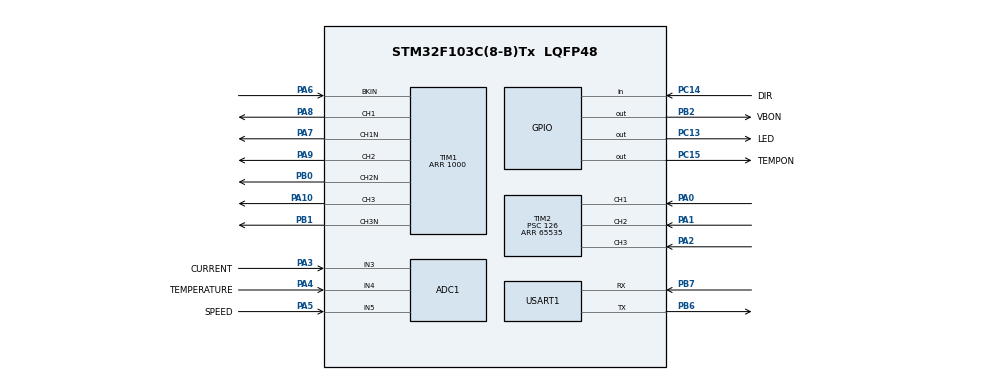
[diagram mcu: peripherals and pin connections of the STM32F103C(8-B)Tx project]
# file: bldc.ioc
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ADC1.Channel-2\#ChannelRegularConversion=ADC_CHANNEL_3
ADC1.NbrOfConversionFlag=1
ADC1.Rank-2\#ChannelRegularConversion=1
ADC1.SamplingTime-2\#ChannelRegularConversion=ADC_SAMPLETIME_1CYCLE_5
ADC1.master=1
Mcu.Family=STM32F1
Mcu.Name=STM32F103C(8-B)Tx
Mcu.Package=LQFP48
NVIC.PriorityGroup=NVIC_PRIORITYGROUP_4
NVIC.TIM1_BRK_IRQn=true\:0\:0\:false\:false\:true\:true\:true
NVIC.TIM1_CC_IRQn=true\:0\:0\:false\:false\:true\:true\:true
NVIC.TIM1_TRG_COM_IRQn=true\:0\:0\:false\:false\:true\:true\:true
NVIC.TIM1_UP_IRQn=true\:0\:0\:false\:false\:true\:true\:true
NVIC.TIM2_IRQn=true\:0\:0\:false\:false\:true\:true\:true
NVIC.USART1_IRQn=true\:0\:0\:false\:false\:true\:true\:true
PA0-WKUP.GPIO_PuPd=GPIO_PULLUP
PA0-WKUP.Signal=S_TIM2_CH1_ETR
PA1.GPIO_PuPd=GPIO_PULLUP
PA1.Signal=S_TIM2_CH2
PA10.GPIO_Speed=GPIO_SPEED_FREQ_HIGH
PA10.Signal=S_TIM1_CH3
PA13.Mode=Serial_Wire
PA13.Signal=SYS_JTMS-SWDIO
PA14.Mode=Serial_Wire
PA14.Signal=SYS_JTCK-SWCLK
PA2.GPIO_PuPd=GPIO_PULLUP
PA2.Signal=S_TIM2_CH3
PA3.GPIO_Label=CURRENT
PA3.Signal=ADCx_IN3
PA4.GPIO_Label=TEMPERATURE
PA4.Signal=ADCx_IN4
PA5.GPIO_Label=SPEED
PA5.Signal=ADCx_IN5
PA6.GPIO_PuPd=GPIO_PULLUP
PA6.Mode=Activate-Break-Input
PA6.Signal=TIM1_BKIN
PA7.GPIO_Speed=GPIO_SPEED_FREQ_HIGH
PA7.Mode=PWM Generation1 CH1 CH1N
PA7.Signal=TIM1_CH1N
PA8.GPIO_Speed=GPIO_SPEED_FREQ_HIGH
PA8.Signal=S_TIM1_CH1
PA9.GPIO_Speed=GPIO_SPEED_FREQ_HIGH
PA9.Signal=S_TIM1_CH2
PB0.GPIO_Speed=GPIO_SPEED_FREQ_HIGH
PB0.Mode=PWM Generation2 CH2 CH2N
PB0.Signal=TIM1_CH2N
PB1.GPIO_Speed=GPIO_SPEED_FREQ_HIGH
PB1.Mode=PWM Generation3 CH3 CH3N
PB1.Signal=TIM1_CH3N
PB2.GPIO_Label=VBON
PB2.Signal=GPIO_Output
PB6.Mode=Asynchronous
PB6.Signal=USART1_TX
PB7.Mode=Asynchronous
PB7.Signal=USART1_RX
PC13-TAMPER-RTC.GPIO_Label=LED
PC13-TAMPER-RTC.Signal=GPIO_Output
PC14-OSC32_IN.GPIO_Label=DIR
PC14-OSC32_IN.Signal=GPIO_Input
PC15-OSC32_OUT.GPIO_Label=TEMPON
PC15-OSC32_OUT.Signal=GPIO_Output
PD0-OSC_IN.Mode=HSE-External-Oscillator
PD0-OSC_IN.Signal=RCC_OSC_IN
PD1-OSC_OUT.Mode=HSE-External-Oscillator
PD1-OSC_OUT.Signal=RCC_OSC_OUT
ProjectManager.HeapSize=0x200
ProjectManager.StackSize=0x400
ProjectManager.TargetToolchain=Other Toolchains (GPDSC)
RCC.ADCPresc=RCC_ADCPCLK2_DIV8
RCC.AHBFreq_Value=72000000
RCC.APB1CLKDivider=RCC_HCLK_DIV2
RCC.APB1Freq_Value=36000000
RCC.APB1TimFreq_Value=72000000
RCC.APB2Freq_Value=72000000
RCC.APB2TimFreq_Value=72000000
RCC.HCLKFreq_Value=72000000
RCC.PLLMUL=RCC_PLL_MUL9
RCC.PLLSourceVirtual=RCC_PLLSOURCE_HSE
RCC.RTCClockSelection=RCC_RTCCLKSOURCE_LSE
RCC.SYSCLKFreq_VALUE=72000000
RCC.SYSCLKSource=RCC_SYSCLKSOURCE_PLLCLK
RCC.USBFreq_Value=72000000
SH.ADCx_IN3.0=ADC1_IN3,IN3
SH.ADCx_IN4.0=ADC1_IN4,IN4
SH.ADCx_IN5.0=ADC1_IN5,IN5
SH.S_TIM1_CH1.0=TIM1_CH1,PWM Generation1 CH1 CH1N
SH.S_TIM1_CH2.0=TIM1_CH2,PWM Generation2 CH2 CH2N
SH.S_TIM1_CH3.0=TIM1_CH3,PWM Generation3 CH3 CH3N
SH.S_TIM2_CH1_ETR.0=TIM2_CH1,Xored_Inputs_Hall_Sensor_Interface
SH.S_TIM2_CH2.0=TIM2_CH2,Xored_Inputs_Hall_Sensor_Interface
SH.S_TIM2_CH3.0=TIM2_CH3,Xored_Inputs_Hall_Sensor_Interface
TIM1.BreakPolarity=TIM_BREAKPOLARITY_LOW
TIM1.Channel-PWM\ Generation1\ CH1\ CH1N=TIM_CHANNEL_1
TIM1.Channel-PWM\ Generation2\ CH2\ CH2N=TIM_CHANNEL_2
TIM1.Channel-PWM\ Generation3\ CH3\ CH3N=TIM_CHANNEL_3
TIM1.OCIdleState_1=TIM_OCIDLESTATE_SET
TIM1.OCIdleState_2=TIM_OCIDLESTATE_SET
TIM1.OCIdleState_3=TIM_OCIDLESTATE_SET
TIM1.OCNIdleState_1=TIM_OCNIDLESTATE_SET
TIM1.OCNIdleState_2=TIM_OCNIDLESTATE_SET
TIM1.OCNIdleState_3=TIM_OCNIDLESTATE_SET
TIM1.Period=1000
TIM1.TIM_MasterSlaveMode=TIM_MASTERSLAVEMODE_ENABLE
TIM2.AutoReloadPreload=TIM_AUTORELOAD_PRELOAD_DISABLE
TIM2.Channel-Output\ Compare4\ No\ Output=TIM_CHANNEL_4
TIM2.Commutation_Delay=100
TIM2.IC1Filter=0x0F
TIM2.Period=65535
TIM2.Prescaler=126
TIM2.Pulse-Output\ Compare4\ No\ Output=1
USART1.VirtualMode=VM_ASYNC
VP_ADC1_TempSens_Input.Mode=IN-TempSens
VP_ADC1_Vref_Input.Mode=IN-Vrefint
VP_TIM1_VS_ClockSourceINT.Mode=Internal
VP_TIM1_VS_ClockSourceITR.Mode=TriggerSource_ITR1
VP_TIM1_VS_ControllerModeReset.Mode=Reset Mode
VP_TIM2_VS_ClockSourceINT.Mode=Internal
VP_TIM2_VS_no_output4.Mode=Output Compare4 No Output
board=custom

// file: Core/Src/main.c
/* USER CODE BEGIN Header */
/**
  ******************************************************************************
  * @file           : main.c
  * @brief          : Main program body
  ******************************************************************************
  * @attention
  *
  * <h2><center>&copy; Copyright (c) 2019 STMicroelectronics.
  * All rights reserved.</center></h2>
  *
  * This software component is licensed by ST under BSD 3-Clause license,
  * the "License"; You may not use this file except in compliance with the
  * License. You may obtain a copy of the License at:
  *                        opensource.org/licenses/BSD-3-Clause
  *
  ******************************************************************************
  */
/* USER CODE END Header */

#include "main.h"

/* USER CODE BEGIN Includes */
#include "bldc.h"
/* USER CODE END Includes */

void SystemClock_Config(void);
static void MX_GPIO_Init(void);
static void MX_TIM1_Init(void);
static void MX_TIM2_Init(void);
static void MX_USART1_UART_Init(void);
static void MX_ADC1_Init(void);

int main(void)
{

  /* MCU Configuration--------------------------------------------------------*/

  /* Reset of all peripherals, Initializes the Flash interface and the Systick. */

  LL_APB2_GRP1_EnableClock(LL_APB2_GRP1_PERIPH_AFIO);
  LL_APB1_GRP1_EnableClock(LL_APB1_GRP1_PERIPH_PWR);

  NVIC_SetPriorityGrouping(NVIC_PRIORITYGROUP_4);

  /* System interrupt init*/

  /** NOJTAG: JTAG-DP Disabled and SW-DP Enabled
  */
  LL_GPIO_AF_Remap_SWJ_NOJTAG();

  /* Configure the system clock */
  SystemClock_Config();

  /* Initialize all configured peripherals */
  MX_GPIO_Init();
  MX_TIM1_Init();
  MX_TIM2_Init();
  MX_USART1_UART_Init();
  MX_ADC1_Init();
  /* USER CODE BEGIN 2 */

  BLDC_SystemInit();

  /* USER CODE END 2 */

  /* Infinite loop */
  while (1)
  {

  }
}

void SystemClock_Config(void)
{
  LL_FLASH_SetLatency(LL_FLASH_LATENCY_2);

   if(LL_FLASH_GetLatency() != LL_FLASH_LATENCY_2)
  {
    Error_Handler();
  }
  LL_RCC_HSE_Enable();

   /* Wait till HSE is ready */
  while(LL_RCC_HSE_IsReady() != 1)
  {

  }
  LL_RCC_PLL_ConfigDomain_SYS(LL_RCC_PLLSOURCE_HSE_DIV_1, LL_RCC_PLL_MUL_9);
  LL_RCC_PLL_Enable();

   /* Wait till PLL is ready */
  while(LL_RCC_PLL_IsReady() != 1)
  {

  }
  LL_RCC_SetAHBPrescaler(LL_RCC_SYSCLK_DIV_1);
  LL_RCC_SetAPB1Prescaler(LL_RCC_APB1_DIV_2);
  LL_RCC_SetAPB2Prescaler(LL_RCC_APB2_DIV_1);
  LL_RCC_SetSysClkSource(LL_RCC_SYS_CLKSOURCE_PLL);

   /* Wait till System clock is ready */
  while(LL_RCC_GetSysClkSource() != LL_RCC_SYS_CLKSOURCE_STATUS_PLL)
  {

  }
  LL_Init1msTick(72000000);
  LL_SYSTICK_SetClkSource(LL_SYSTICK_CLKSOURCE_HCLK);
  LL_SetSystemCoreClock(72000000);
  LL_RCC_SetADCClockSource(LL_RCC_ADC_CLKSRC_PCLK2_DIV_8);
}

static void MX_ADC1_Init(void)
{

  LL_ADC_InitTypeDef ADC_InitStruct = {0};
  LL_ADC_CommonInitTypeDef ADC_CommonInitStruct = {0};
  LL_ADC_REG_InitTypeDef ADC_REG_InitStruct = {0};

  LL_GPIO_InitTypeDef GPIO_InitStruct = {0};

  /* Peripheral clock enable */
  LL_APB2_GRP1_EnableClock(LL_APB2_GRP1_PERIPH_ADC1);

  LL_APB2_GRP1_EnableClock(LL_APB2_GRP1_PERIPH_GPIOA);
  /**ADC1 GPIO Configuration
  PA3   ------> ADC1_IN3
  PA4   ------> ADC1_IN4
  PA5   ------> ADC1_IN5
  */
  GPIO_InitStruct.Pin = CURRENT_Pin|TEMPERATURE_Pin|SPEED_Pin;
  GPIO_InitStruct.Mode = LL_GPIO_MODE_ANALOG;
  LL_GPIO_Init(GPIOA, &GPIO_InitStruct);

  /** Common config
  */
  ADC_InitStruct.DataAlignment = LL_ADC_DATA_ALIGN_RIGHT;
  ADC_InitStruct.SequencersScanMode = LL_ADC_SEQ_SCAN_DISABLE;
  LL_ADC_Init(ADC1, &ADC_InitStruct);
  ADC_CommonInitStruct.Multimode = LL_ADC_MULTI_INDEPENDENT;
  LL_ADC_CommonInit(__LL_ADC_COMMON_INSTANCE(ADC1), &ADC_CommonInitStruct);
  ADC_REG_InitStruct.TriggerSource = LL_ADC_REG_TRIG_SOFTWARE;
  ADC_REG_InitStruct.SequencerLength = LL_ADC_REG_SEQ_SCAN_DISABLE;
  ADC_REG_InitStruct.SequencerDiscont = LL_ADC_REG_SEQ_DISCONT_DISABLE;
  ADC_REG_InitStruct.ContinuousMode = LL_ADC_REG_CONV_SINGLE;
  ADC_REG_InitStruct.DMATransfer = LL_ADC_REG_DMA_TRANSFER_NONE;
  LL_ADC_REG_Init(ADC1, &ADC_REG_InitStruct);
  /** Configure Regular Channel
  */
  LL_ADC_REG_SetSequencerRanks(ADC1, LL_ADC_REG_RANK_1, LL_ADC_CHANNEL_3);
  LL_ADC_SetChannelSamplingTime(ADC1, LL_ADC_CHANNEL_3, LL_ADC_SAMPLINGTIME_1CYCLE_5);

}

static void MX_TIM1_Init(void)
{

  LL_TIM_InitTypeDef TIM_InitStruct = {0};
  LL_TIM_OC_InitTypeDef TIM_OC_InitStruct = {0};
  LL_TIM_BDTR_InitTypeDef TIM_BDTRInitStruct = {0};

  LL_GPIO_InitTypeDef GPIO_InitStruct = {0};

  /* Peripheral clock enable */
  LL_APB2_GRP1_EnableClock(LL_APB2_GRP1_PERIPH_TIM1);

  LL_APB2_GRP1_EnableClock(LL_APB2_GRP1_PERIPH_GPIOA);
  /**TIM1 GPIO Configuration
  PA6   ------> TIM1_BKIN
  */
  GPIO_InitStruct.Pin = LL_GPIO_PIN_6;
  GPIO_InitStruct.Mode = LL_GPIO_MODE_INPUT;
  GPIO_InitStruct.Pull = LL_GPIO_PULL_UP;
  LL_GPIO_Init(GPIOA, &GPIO_InitStruct);

  /* TIM1 interrupt Init */
  NVIC_SetPriority(TIM1_BRK_IRQn, NVIC_EncodePriority(NVIC_GetPriorityGrouping(),0, 0));
  NVIC_EnableIRQ(TIM1_BRK_IRQn);
  NVIC_SetPriority(TIM1_UP_IRQn, NVIC_EncodePriority(NVIC_GetPriorityGrouping(),0, 0));
  NVIC_EnableIRQ(TIM1_UP_IRQn);
  NVIC_SetPriority(TIM1_TRG_COM_IRQn, NVIC_EncodePriority(NVIC_GetPriorityGrouping(),0, 0));
  NVIC_EnableIRQ(TIM1_TRG_COM_IRQn);
  NVIC_SetPriority(TIM1_CC_IRQn, NVIC_EncodePriority(NVIC_GetPriorityGrouping(),0, 0));
  NVIC_EnableIRQ(TIM1_CC_IRQn);

  TIM_InitStruct.Prescaler = 0;
  TIM_InitStruct.CounterMode = LL_TIM_COUNTERMODE_UP;
  TIM_InitStruct.Autoreload = 1000;
  TIM_InitStruct.ClockDivision = LL_TIM_CLOCKDIVISION_DIV1;
  TIM_InitStruct.RepetitionCounter = 0;
  LL_TIM_Init(TIM1, &TIM_InitStruct);
  LL_TIM_DisableARRPreload(TIM1);
  LL_TIM_SetClockSource(TIM1, LL_TIM_CLOCKSOURCE_INTERNAL);
  LL_TIM_OC_EnablePreload(TIM1, LL_TIM_CHANNEL_CH1);
  TIM_OC_InitStruct.OCMode = LL_TIM_OCMODE_PWM1;
  TIM_OC_InitStruct.OCState = LL_TIM_OCSTATE_DISABLE;
  TIM_OC_InitStruct.OCNState = LL_TIM_OCSTATE_DISABLE;
  TIM_OC_InitStruct.CompareValue = 0;
  TIM_OC_InitStruct.OCPolarity = LL_TIM_OCPOLARITY_HIGH;
  TIM_OC_InitStruct.OCNPolarity = LL_TIM_OCPOLARITY_HIGH;
  TIM_OC_InitStruct.OCIdleState = LL_TIM_OCIDLESTATE_HIGH;
  TIM_OC_InitStruct.OCNIdleState = LL_TIM_OCIDLESTATE_HIGH;
  LL_TIM_OC_Init(TIM1, LL_TIM_CHANNEL_CH1, &TIM_OC_InitStruct);
  LL_TIM_OC_DisableFast(TIM1, LL_TIM_CHANNEL_CH1);
  LL_TIM_OC_EnablePreload(TIM1, LL_TIM_CHANNEL_CH2);
  TIM_OC_InitStruct.OCState = LL_TIM_OCSTATE_DISABLE;
  TIM_OC_InitStruct.OCNState = LL_TIM_OCSTATE_DISABLE;
  LL_TIM_OC_Init(TIM1, LL_TIM_CHANNEL_CH2, &TIM_OC_InitStruct);
  LL_TIM_OC_DisableFast(TIM1, LL_TIM_CHANNEL_CH2);
  LL_TIM_OC_EnablePreload(TIM1, LL_TIM_CHANNEL_CH3);
  TIM_OC_InitStruct.OCState = LL_TIM_OCSTATE_DISABLE;
  TIM_OC_InitStruct.OCNState = LL_TIM_OCSTATE_DISABLE;
  LL_TIM_OC_Init(TIM1, LL_TIM_CHANNEL_CH3, &TIM_OC_InitStruct);
  LL_TIM_OC_DisableFast(TIM1, LL_TIM_CHANNEL_CH3);
  LL_TIM_SetTriggerInput(TIM1, LL_TIM_TS_ITR1);
  LL_TIM_SetSlaveMode(TIM1, LL_TIM_SLAVEMODE_RESET);
  LL_TIM_DisableIT_TRIG(TIM1);
  LL_TIM_DisableDMAReq_TRIG(TIM1);
  LL_TIM_SetTriggerOutput(TIM1, LL_TIM_TRGO_RESET);
  LL_TIM_EnableMasterSlaveMode(TIM1);
  TIM_BDTRInitStruct.OSSRState = LL_TIM_OSSR_DISABLE;
  TIM_BDTRInitStruct.OSSIState = LL_TIM_OSSI_DISABLE;
  TIM_BDTRInitStruct.LockLevel = LL_TIM_LOCKLEVEL_OFF;
  TIM_BDTRInitStruct.DeadTime = 0;
  TIM_BDTRInitStruct.BreakState = LL_TIM_BREAK_ENABLE;
  TIM_BDTRInitStruct.BreakPolarity = LL_TIM_BREAK_POLARITY_LOW;
  TIM_BDTRInitStruct.AutomaticOutput = LL_TIM_AUTOMATICOUTPUT_DISABLE;
  LL_TIM_BDTR_Init(TIM1, &TIM_BDTRInitStruct);
  LL_APB2_GRP1_EnableClock(LL_APB2_GRP1_PERIPH_GPIOA);
  LL_APB2_GRP1_EnableClock(LL_APB2_GRP1_PERIPH_GPIOB);
  /**TIM1 GPIO Configuration
  PA7   ------> TIM1_CH1N
  PB0   ------> TIM1_CH2N
  PB1   ------> TIM1_CH3N
  PA8   ------> TIM1_CH1
  PA9   ------> TIM1_CH2
  PA10   ------> TIM1_CH3
  */
  GPIO_InitStruct.Pin = LL_GPIO_PIN_7|LL_GPIO_PIN_8|LL_GPIO_PIN_9|LL_GPIO_PIN_10;
  GPIO_InitStruct.Mode = LL_GPIO_MODE_ALTERNATE;
  GPIO_InitStruct.Speed = LL_GPIO_SPEED_FREQ_HIGH;
  GPIO_InitStruct.OutputType = LL_GPIO_OUTPUT_PUSHPULL;
  LL_GPIO_Init(GPIOA, &GPIO_InitStruct);

  GPIO_InitStruct.Pin = LL_GPIO_PIN_0|LL_GPIO_PIN_1;
  GPIO_InitStruct.Mode = LL_GPIO_MODE_ALTERNATE;
  GPIO_InitStruct.Speed = LL_GPIO_SPEED_FREQ_HIGH;
  GPIO_InitStruct.OutputType = LL_GPIO_OUTPUT_PUSHPULL;
  LL_GPIO_Init(GPIOB, &GPIO_InitStruct);

  LL_GPIO_AF_RemapPartial_TIM1();

}

static void MX_TIM2_Init(void)
{

  LL_TIM_InitTypeDef TIM_InitStruct = {0};
  LL_TIM_OC_InitTypeDef TIM_OC_InitStruct = {0};

  LL_GPIO_InitTypeDef GPIO_InitStruct = {0};

  /* Peripheral clock enable */
  LL_APB1_GRP1_EnableClock(LL_APB1_GRP1_PERIPH_TIM2);

  LL_APB2_GRP1_EnableClock(LL_APB2_GRP1_PERIPH_GPIOA);
  /**TIM2 GPIO Configuration
  PA0-WKUP   ------> TIM2_CH1
  PA1   ------> TIM2_CH2
  PA2   ------> TIM2_CH3
  */
  GPIO_InitStruct.Pin = LL_GPIO_PIN_0|LL_GPIO_PIN_1|LL_GPIO_PIN_2;
  GPIO_InitStruct.Mode = LL_GPIO_MODE_INPUT;
  GPIO_InitStruct.Pull = LL_GPIO_PULL_UP;
  LL_GPIO_Init(GPIOA, &GPIO_InitStruct);

  /* TIM2 interrupt Init */
  NVIC_SetPriority(TIM2_IRQn, NVIC_EncodePriority(NVIC_GetPriorityGrouping(),0, 0));
  NVIC_EnableIRQ(TIM2_IRQn);

  TIM_InitStruct.Prescaler = 126;
  TIM_InitStruct.CounterMode = LL_TIM_COUNTERMODE_UP;
  TIM_InitStruct.Autoreload = 65535;
  TIM_InitStruct.ClockDivision = LL_TIM_CLOCKDIVISION_DIV1;
  LL_TIM_Init(TIM2, &TIM_InitStruct);
  LL_TIM_DisableARRPreload(TIM2);
  LL_TIM_SetClockSource(TIM2, LL_TIM_CLOCKSOURCE_INTERNAL);
  TIM_OC_InitStruct.OCMode = LL_TIM_OCMODE_FROZEN;
  TIM_OC_InitStruct.OCState = LL_TIM_OCSTATE_DISABLE;
  TIM_OC_InitStruct.OCNState = LL_TIM_OCSTATE_DISABLE;
  TIM_OC_InitStruct.CompareValue = 1;
  TIM_OC_InitStruct.OCPolarity = LL_TIM_OCPOLARITY_HIGH;
  LL_TIM_OC_Init(TIM2, LL_TIM_CHANNEL_CH4, &TIM_OC_InitStruct);
  LL_TIM_OC_DisableFast(TIM2, LL_TIM_CHANNEL_CH4);
  LL_TIM_CC_DisableChannel(TIM2, LL_TIM_CHANNEL_CH1 | LL_TIM_CHANNEL_CH2);
  LL_TIM_IC_SetActiveInput(TIM2, LL_TIM_CHANNEL_CH1, LL_TIM_ACTIVEINPUT_TRC);
  LL_TIM_IC_SetPrescaler(TIM2, LL_TIM_CHANNEL_CH1, LL_TIM_ICPSC_DIV1);
  LL_TIM_IC_SetFilter(TIM2, LL_TIM_CHANNEL_CH1, LL_TIM_IC_FILTER_FDIV32_N8);
  LL_TIM_IC_SetPolarity(TIM2, LL_TIM_CHANNEL_CH1, LL_TIM_IC_POLARITY_RISING);
  LL_TIM_IC_EnableXORCombination(TIM2);
  LL_TIM_SetTriggerInput(TIM2, LL_TIM_TS_TI1F_ED);
  LL_TIM_SetSlaveMode(TIM2, LL_TIM_SLAVEMODE_RESET);
  TIM_OC_InitStruct.OCMode = LL_TIM_OCMODE_PWM2;
  TIM_OC_InitStruct.OCState = LL_TIM_OCSTATE_DISABLE;
  TIM_OC_InitStruct.OCNState = LL_TIM_OCSTATE_DISABLE;
  TIM_OC_InitStruct.CompareValue = 100;
  TIM_OC_InitStruct.OCPolarity = LL_TIM_OCPOLARITY_HIGH;
  TIM_OC_InitStruct.OCNPolarity = LL_TIM_OCPOLARITY_HIGH;
  TIM_OC_InitStruct.OCIdleState = LL_TIM_OCIDLESTATE_LOW;
  TIM_OC_InitStruct.OCNIdleState = LL_TIM_OCIDLESTATE_LOW;

  LL_TIM_OC_Init(TIM2, LL_TIM_CHANNEL_CH2, &TIM_OC_InitStruct);
  LL_TIM_OC_DisableFast(TIM2, LL_TIM_CHANNEL_CH2);
  LL_TIM_SetTriggerOutput(TIM2, LL_TIM_TRGO_OC2REF);
  LL_TIM_DisableMasterSlaveMode(TIM2);

}

static void MX_USART1_UART_Init(void)
{

  LL_USART_InitTypeDef USART_InitStruct = {0};

  LL_GPIO_InitTypeDef GPIO_InitStruct = {0};

  /* Peripheral clock enable */
  LL_APB2_GRP1_EnableClock(LL_APB2_GRP1_PERIPH_USART1);

  LL_APB2_GRP1_EnableClock(LL_APB2_GRP1_PERIPH_GPIOB);
  /**USART1 GPIO Configuration
  PB6   ------> USART1_TX
  PB7   ------> USART1_RX
  */
  GPIO_InitStruct.Pin = LL_GPIO_PIN_6;
  GPIO_InitStruct.Mode = LL_GPIO_MODE_ALTERNATE;
  GPIO_InitStruct.Speed = LL_GPIO_SPEED_FREQ_HIGH;
  GPIO_InitStruct.OutputType = LL_GPIO_OUTPUT_PUSHPULL;
  LL_GPIO_Init(GPIOB, &GPIO_InitStruct);

  GPIO_InitStruct.Pin = LL_GPIO_PIN_7;
  GPIO_InitStruct.Mode = LL_GPIO_MODE_FLOATING;
  LL_GPIO_Init(GPIOB, &GPIO_InitStruct);

  LL_GPIO_AF_EnableRemap_USART1();

  /* USART1 interrupt Init */
  NVIC_SetPriority(USART1_IRQn, NVIC_EncodePriority(NVIC_GetPriorityGrouping(),0, 0));
  NVIC_EnableIRQ(USART1_IRQn);

  USART_InitStruct.BaudRate = 115200;
  USART_InitStruct.DataWidth = LL_USART_DATAWIDTH_8B;
  USART_InitStruct.StopBits = LL_USART_STOPBITS_1;
  USART_InitStruct.Parity = LL_USART_PARITY_NONE;
  USART_InitStruct.TransferDirection = LL_USART_DIRECTION_TX_RX;
  USART_InitStruct.HardwareFlowControl = LL_USART_HWCONTROL_NONE;
  USART_InitStruct.OverSampling = LL_USART_OVERSAMPLING_16;
  LL_USART_Init(USART1, &USART_InitStruct);
  LL_USART_ConfigAsyncMode(USART1);
  LL_USART_Enable(USART1);

}

static void MX_GPIO_Init(void)
{
  LL_GPIO_InitTypeDef GPIO_InitStruct = {0};

  /* GPIO Ports Clock Enable */
  LL_APB2_GRP1_EnableClock(LL_APB2_GRP1_PERIPH_GPIOC);
  LL_APB2_GRP1_EnableClock(LL_APB2_GRP1_PERIPH_GPIOD);
  LL_APB2_GRP1_EnableClock(LL_APB2_GRP1_PERIPH_GPIOA);
  LL_APB2_GRP1_EnableClock(LL_APB2_GRP1_PERIPH_GPIOB);

  /**/
  LL_GPIO_ResetOutputPin(GPIOC, LED_Pin|TEMPON_Pin);

  /**/
  LL_GPIO_ResetOutputPin(VBON_GPIO_Port, VBON_Pin);

  /**/
  GPIO_InitStruct.Pin = LED_Pin|TEMPON_Pin;
  GPIO_InitStruct.Mode = LL_GPIO_MODE_OUTPUT;
  GPIO_InitStruct.Speed = LL_GPIO_SPEED_FREQ_LOW;
  GPIO_InitStruct.OutputType = LL_GPIO_OUTPUT_PUSHPULL;
  LL_GPIO_Init(GPIOC, &GPIO_InitStruct);

  /**/
  GPIO_InitStruct.Pin = DIR_Pin;
  GPIO_InitStruct.Mode = LL_GPIO_MODE_FLOATING;
  LL_GPIO_Init(DIR_GPIO_Port, &GPIO_InitStruct);

  /**/
  GPIO_InitStruct.Pin = VBON_Pin;
  GPIO_InitStruct.Mode = LL_GPIO_MODE_OUTPUT;
  GPIO_InitStruct.Speed = LL_GPIO_SPEED_FREQ_LOW;
  GPIO_InitStruct.OutputType = LL_GPIO_OUTPUT_PUSHPULL;
  LL_GPIO_Init(VBON_GPIO_Port, &GPIO_InitStruct);

}

void Error_Handler(void)
{
}

/************************ (C) COPYRIGHT STMicroelectronics *****END OF FILE****/
